# SPC1068 register map
File version: 20180100_70611510
CPU: CM3 r2p1, little endian, MPU, no FPU, 4 interrupt priority bits
Registers are 32-bit, read-write, reset 0x0 unless marked. A register's access mark holds for its fields unless they carry their own. Offsets are from the block's base; [hi:lo] are bit positions; 'fields as' and 'values as' point back to an identical list.

## PGA — Split from ADC
Base 0x4000A000
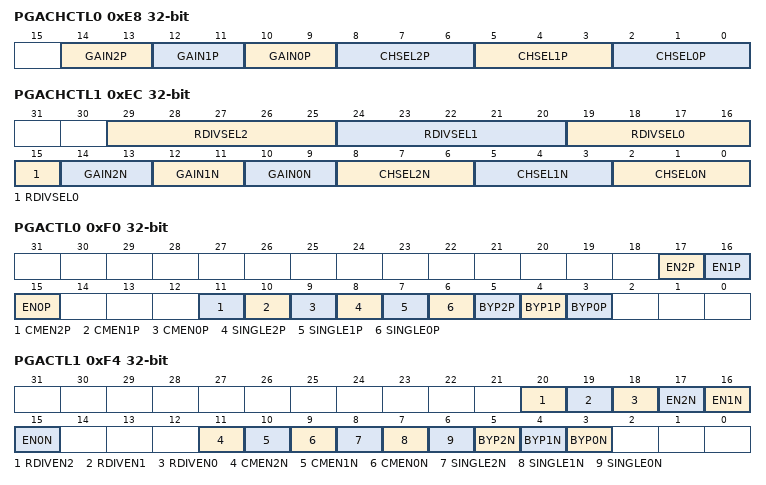
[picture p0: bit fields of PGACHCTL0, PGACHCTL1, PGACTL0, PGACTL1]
0xE8 PGACHCTL0 — PGA Channel Select Control Register 0
  [14:13] GAIN2P — Select Gain for positive input of PGA 2
    0=SINGLE_2X_DIFF_4X (2x single-ended mode / 4x coupled mode); 1=SINGLE_4X_DIFF_8X (4x single-ended mode / 8x coupled mode); 2=SINGLE_8X_DIFF_16X (8x single-ended mode / 16x coupled mode); 3=SINGLE_16X_DIFF_32X (16x single-ended mode / 32x coupled mode)
  [12:11] GAIN1P — Select Gain for positive input of PGA 1
    values as GAIN2P
  [10:9] GAIN0P — Select Gain for positive input of PGA 0
    values as GAIN2P
  [8:6] CHSEL2P — Input channel selection for positive input of PGA 2
    0=VSSA (VSSA (GND)); 1=TSENSOR1 (T-sensor out 1); 2=ADC3 (GPIO4); 3=ADC13 (GPIO14); 4=ADC6 (GPIO7); 5=ADC7 (GPIO8); 6=ADC14 (GPIO15); 7=RESDIV2
  [5:3] CHSEL1P — Input channel selection for positive input of PGA 1
    0=VSSA (VSSA (GND)); 1=VDAC_HI; 2=ADC1 (GPIO2); 3=ADC11 (GPIO12); 4=ADC4 (GPIO5); 5=ADC7 (GPIO8); 6=ADC14 (GPIO15); 7=RESDIV1
  [2:0] CHSEL0P — Input channel selection for positive input of PGA 0
    0=VSSA (VSSA (GND)); 1=VDDR12_ANA; 2=ADC5 (GPIO6); 3=ADC9 (GPIO10); 4=ADC2 (GPIO3); 5=ADC7 (GPIO8); 6=ADC14 (GPIO15); 7=RESDIV0
0xEC PGACHCTL1 — PGA Channel Select Control Register 1
  [29:25] RDIVSEL2 — Select output voltage of Resistor-Divider for PGA 2. RESDIV 2 OUTPUT = RDIVSEL2*VDDA/32
  [24:20] RDIVSEL1 — Select output voltage of Resistor-Divider for PGA 1. RESDIV 1 OUTPUT = RDIVSEL1*VDDA/32
  [19:15] RDIVSEL0 — Select output voltage of Resistor-Divider for PGA 0. RESDIV 0 OUTPUT = RDIVSEL0*VDDA/32
  [14:13] GAIN2N — Select Gain for negative input of PGA 2
    values as PGACHCTL0.GAIN2P
  [12:11] GAIN1N — Select Gain for negative input of PGA 1
    values as PGACHCTL0.GAIN2P
  [10:9] GAIN0N — Select Gain for negative input of PGA 0
    values as PGACHCTL0.GAIN2P
  [8:6] CHSEL2N — Input channel selection for negative input of PGA 2
    0=VSSA (VSSA (GND)); 1=TSENSOR0 (T-sensor out 0); 2=ADC10 (GPIO11); 3=ADC12 (GPIO13); 4=ADC5 (GPIO6); 5=ADC0 (GPIO1); 6=ADC15 (GPIO16); 7=RESDIV2
  [5:3] CHSEL1N — Input channel selection for negative input of PGA 1
    0=VSSA; 1=ADC_1dot2 (ADC 1.2V Reference); 2=ADC8 (GPIO9); 3=ADC10 (GPIO11); 4=ADC3 (GPIO4); 5=ADC0 (GPIO1); 6=ADC15 (GPIO16); 7=RESDIV1
  [2:0] CHSEL0N — Input channel selection for negative input of PGA 0
    0=VSSA; 1=TEST (GPIO25); 2=ADC9 (GPIO10); 3=ADC8 (GPIO9); 4=ADC1 (GPIO2); 5=ADC0 (GPIO1); 6=ADC15 (GPIO16); 7=RESDIV0
0xF0 PGACTL0 — PGA Control Register 0
  [17] EN2P — Enable the positive OP of PGA 2
    0=DISABLE (Disable the positive OP of PGA 2); 1=ENABLE (Enable the positive OP of PGA 2)
  [16] EN1P — Enable the positive OP of PGA 1
    0=DISABLE (Disable the positive OP of PGA 1); 1=ENABLE (Enable the positive OP of PGA 1)
  [15] EN0P — Enable the positive OP of PGA 0
    0=DISABLE (Disable the positive OP of PGA 0); 1=ENABLE (Enable the positive OP of PGA 0)
  [11] CMEN2P — Enable using the input from the positive OP of PGA 2 as a common voltage for the differential output
    0=DISABLE (Disable this function); 1=ENABLE (Enable this function)
  [10] CMEN1P — Enable using the input from the positive OP of PGA 1 as a common voltage for the differential output
    values as CMEN2P
  [9] CMEN0P — Enable using the input from the positive OP of PGA 0 as a common voltage for the differential output
    values as CMEN2P
  [8] SINGLE2P — Single-ended mode enable for the positive OP of PGA 2
    values as CMEN2P
  [7] SINGLE1P — Single-ended mode enable for the positive OP of PGA 1
    values as CMEN2P
  [6] SINGLE0P — Single-ended mode enable for the positive OP of PGA 0
    values as CMEN2P
  [5] BYP2P — Bypass the positive OP of PGA 2. Input from the positive OP of PGA 2 will be sent to ADC directly.
    values as CMEN2P
  [4] BYP1P — Bypass the positive OP of PGA 1. Input from the positive OP of PGA 1 will be sent to ADC directly.
    values as CMEN2P
  [3] BYP0P — Bypass the positive OP of PGA 0. Input from the positive OP of PGA 0 will be sent to ADC directly.
    values as CMEN2P
0xF4 PGACTL1 — PGA Control Register 1
  [20] RDIVEN2 — Enable Resistor-Divider(RESDIV) 2
    values as PGACTL0.CMEN2P
  [19] RDIVEN1 — Enable Resistor-Divider(RESDIV) 1
    values as PGACTL0.CMEN2P
  [18] RDIVEN0 — Enable Resistor-Divider(RESDIV) 0
    values as PGACTL0.CMEN2P
  [17] EN2N — Enable the negative OP of PGA 2
    values as PGACTL0.EN2P
  [16] EN1N — Enable the negative OP of PGA 1
    values as PGACTL0.EN1P
  [15] EN0N — Enable the negative OP of PGA 0
    values as PGACTL0.EN0P
  [11] CMEN2N — Enable using the input from the negative OP of PGA 2 as a common voltage for the differential output
    values as PGACTL0.CMEN2P
  [10] CMEN1N — Enable using the input from the negative OP of PGA 1 as a common voltage for the differential output
    values as PGACTL0.CMEN2P
  [9] CMEN0N — Enable using the input from the negative OP of PGA 0 as a common voltage for the differential output
    values as PGACTL0.CMEN2P
  [8] SINGLE2N — Single-ended mode enable for the negative OP of PGA 2
    values as PGACTL0.CMEN2P
  [7] SINGLE1N — Single-ended mode enable for the negative OP of PGA 1
    values as PGACTL0.CMEN2P
  [6] SINGLE0N — Single-ended mode enable for the negative OP of PGA 0
    values as PGACTL0.CMEN2P
  [5] BYP2N — Bypass the negative OP of PGA 2. Input from the negative OP of PGA 2 will be sent to ADC directly.
    values as PGACTL0.CMEN2P
  [4] BYP1N — Bypass the negative OP of PGA 1. Input from the negative OP of PGA 1 will be sent to ADC directly.
    values as PGACTL0.CMEN2P
  [3] BYP0N — Bypass the negative OP of PGA 0. Input from the negative OP of PGA 0 will be sent to ADC directly.
    values as PGACTL0.CMEN2P
